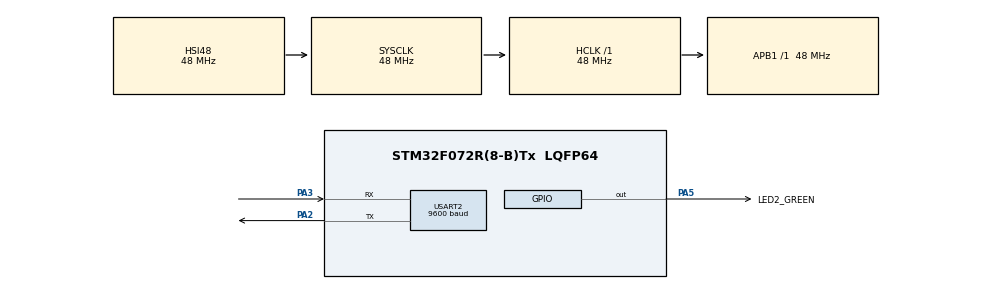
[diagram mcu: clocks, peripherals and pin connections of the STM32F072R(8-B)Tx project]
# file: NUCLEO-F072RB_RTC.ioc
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Mcu.Family=STM32F0
Mcu.Name=STM32F072R(8-B)Tx
Mcu.Package=LQFP64
NVIC.RTC_IRQn=true\:0\:0\:false\:false\:true
PA13.Mode=Serial_Wire
PA13.Signal=SYS_SWDIO
PA14.Mode=Serial_Wire
PA14.Signal=SYS_SWCLK
PA2.Mode=Asynchronous
PA2.Signal=USART2_TX
PA3.Mode=Asynchronous
PA3.Signal=USART2_RX
PA5.GPIO_Label=LED2_GREEN
PA5.Signal=GPIO_Output
ProjectManager.HeapSize=0x200
ProjectManager.StackSize=0x400
ProjectManager.TargetToolchain=EWARM
RCC.AHBFreq_Value=48000000
RCC.APB1Freq_Value=48000000
RCC.APB1TimFreq_Value=48000000
RCC.HCLKFreq_Value=48000000
RCC.SYSCLKFreq_VALUE=48000000
RCC.SYSCLKSource=RCC_SYSCLKSOURCE_HSI48
RTC.Date=30
RTC.Hours=14
RTC.Minutes=10
RTC.Month=RTC_MONTH_AUGUST
RTC.Seconds=5
RTC.WeekDay=RTC_WEEKDAY_TUESDAY
RTC.Year=16
USART2.BaudRate=9600
USART2.WordLength=UART_WORDLENGTH_8B
VP_RTC_VS_RTC_Activate.Mode=RTC_Enabled
VP_RTC_VS_RTC_Calendar.Mode=RTC_Calendar
VP_RTC_VS_RTC_WakeUp_intern.Mode=WakeUp
board=NUCLEO-F072RB_RTC

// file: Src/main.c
/**
  ******************************************************************************
  * File Name          : main.c
  * Description        : Main program body
  ******************************************************************************
  *
  * COPYRIGHT(c) 2016 STMicroelectronics
  *
  * Redistribution and use in source and binary forms, with or without modification,
  * are permitted provided that the following conditions are met:
  *   1. Redistributions of source code must retain the above copyright notice,
  *      this list of conditions and the following disclaimer.
  *   2. Redistributions in binary form must reproduce the above copyright notice,
  *      this list of conditions and the following disclaimer in the documentation
  *      and/or other materials provided with the distribution.
  *   3. Neither the name of STMicroelectronics nor the names of its contributors
  *      may be used to endorse or promote products derived from this software
  *      without specific prior written permission.
  *
  * THIS SOFTWARE IS PROVIDED BY THE COPYRIGHT HOLDERS AND CONTRIBUTORS "AS IS"
  * AND ANY EXPRESS OR IMPLIED WARRANTIES, INCLUDING, BUT NOT LIMITED TO, THE
  * IMPLIED WARRANTIES OF MERCHANTABILITY AND FITNESS FOR A PARTICULAR PURPOSE ARE
  * DISCLAIMED. IN NO EVENT SHALL THE COPYRIGHT HOLDER OR CONTRIBUTORS BE LIABLE
  * FOR ANY DIRECT, INDIRECT, INCIDENTAL, SPECIAL, EXEMPLARY, OR CONSEQUENTIAL
  * DAMAGES (INCLUDING, BUT NOT LIMITED TO, PROCUREMENT OF SUBSTITUTE GOODS OR
  * SERVICES; LOSS OF USE, DATA, OR PROFITS; OR BUSINESS INTERRUPTION) HOWEVER
  * CAUSED AND ON ANY THEORY OF LIABILITY, WHETHER IN CONTRACT, STRICT LIABILITY,
  * OR TORT (INCLUDING NEGLIGENCE OR OTHERWISE) ARISING IN ANY WAY OUT OF THE USE
  * OF THIS SOFTWARE, EVEN IF ADVISED OF THE POSSIBILITY OF SUCH DAMAGE.
  *
  ******************************************************************************
  */
#include "main.h"
#include "stm32f0xx_hal.h"
#include "rtc.h"
#include "usart.h"
#include "gpio.h"

/* USER CODE BEGIN Includes */
//------------------------------------------------------------------------------
/* Projeto    : NUCLEO-F072RB_RTC
 * MCU        : STM32F072RB (NUCLEO-F072RB)
 * Copyright  : Atribuição (CC BY 4.0) Diego Moreno
 * Versão     : 1.0.0
 * Data	      : 10/09/2016
 * Descrição  : Atualiza data e hora do RTC e manda uma string update via UART.
 *		NUCLEO-F072RB Schematics - http://migre.me/tVEOR
 */

/* Includes */
#include <stdio.h>
#include <string.h>

//------------------------------------------------------------------------------
/* USER CODE END Includes */

/* USER CODE BEGIN PV */
/* Private variables ---------------------------------------------------------*/
RTC_TimeTypeDef struct_time;
RTC_DateTypeDef struct_date;

char str_hora_data[50];
/* USER CODE END PV */

void SystemClock_Config(void);
void Error_Handler(void);

/* USER CODE BEGIN PFP */
/* Private function prototypes -----------------------------------------------*/
void RTC_hora_data(void);
/* USER CODE END PFP */

int main(void)
{

  /* MCU Configuration----------------------------------------------------------*/

  /* Reset of all peripherals, Initializes the Flash interface and the Systick. */
  HAL_Init();

  /* Configure the system clock */
  SystemClock_Config();

  /* Initialize all configured peripherals */
  MX_GPIO_Init();
  MX_RTC_Init();
  MX_USART2_UART_Init();

  /* USER CODE BEGIN 2 */

  //Setar o horário inicial
  struct_time.Hours = 0x20;
  struct_time.Minutes = 0x35;
  struct_time.Seconds = 0x45;
  if(HAL_RTC_SetTime(&hrtc, &struct_time, RTC_FORMAT_BCD) != HAL_OK)
  {
    Error_Handler();
  }

  //Setar a data inicial
  struct_date.WeekDay = RTC_WEEKDAY_TUESDAY;
  struct_date.Month = RTC_MONTH_AUGUST;
  struct_date.Date = 0x03;
  struct_date.Year = 0x16;
  if(HAL_RTC_SetDate(&hrtc, &struct_date, RTC_FORMAT_BCD) != HAL_OK)
  {
    Error_Handler();
  }

  /* USER CODE END 2 */

  /* Infinite loop */
  while (1)
  {

  /* USER CODE BEGIN 3 */

    RTC_hora_data();
    HAL_Delay(999);
  }
  /* USER CODE END 3 */

}

/** System Clock Configuration
*/
void SystemClock_Config(void)
{

  RCC_OscInitTypeDef RCC_OscInitStruct;
  RCC_ClkInitTypeDef RCC_ClkInitStruct;
  RCC_PeriphCLKInitTypeDef PeriphClkInit;

    /**Initializes the CPU, AHB and APB busses clocks
    */
  RCC_OscInitStruct.OscillatorType = RCC_OSCILLATORTYPE_HSI48|RCC_OSCILLATORTYPE_LSI;
  RCC_OscInitStruct.HSI48State = RCC_HSI48_ON;
  RCC_OscInitStruct.LSIState = RCC_LSI_ON;
  RCC_OscInitStruct.PLL.PLLState = RCC_PLL_NONE;
  if (HAL_RCC_OscConfig(&RCC_OscInitStruct) != HAL_OK)
  {
    Error_Handler();
  }

    /**Initializes the CPU, AHB and APB busses clocks
    */
  RCC_ClkInitStruct.ClockType = RCC_CLOCKTYPE_HCLK|RCC_CLOCKTYPE_SYSCLK
                              |RCC_CLOCKTYPE_PCLK1;
  RCC_ClkInitStruct.SYSCLKSource = RCC_SYSCLKSOURCE_HSI48;
  RCC_ClkInitStruct.AHBCLKDivider = RCC_SYSCLK_DIV1;
  RCC_ClkInitStruct.APB1CLKDivider = RCC_HCLK_DIV1;

  if (HAL_RCC_ClockConfig(&RCC_ClkInitStruct, FLASH_LATENCY_1) != HAL_OK)
  {
    Error_Handler();
  }

  PeriphClkInit.PeriphClockSelection = RCC_PERIPHCLK_USART2|RCC_PERIPHCLK_RTC;
  PeriphClkInit.Usart2ClockSelection = RCC_USART2CLKSOURCE_PCLK1;
  PeriphClkInit.RTCClockSelection = RCC_RTCCLKSOURCE_LSI;
  if (HAL_RCCEx_PeriphCLKConfig(&PeriphClkInit) != HAL_OK)
  {
    Error_Handler();
  }

    /**Configure the Systick interrupt time
    */
  HAL_SYSTICK_Config(HAL_RCC_GetHCLKFreq()/1000);

    /**Configure the Systick
    */
  HAL_SYSTICK_CLKSourceConfig(SYSTICK_CLKSOURCE_HCLK);

  /* SysTick_IRQn interrupt configuration */
  HAL_NVIC_SetPriority(SysTick_IRQn, 0, 0);
}

/* USER CODE BEGIN 4 */
//------------------------------------------------------------------------------

/* Subrotina  : RTC_hora_data
 * Descrição  : Atualiza hora e data e manda na serial.
 * Parâmetros : void
 * Retorno    : void
 */
void RTC_hora_data(void)
{
  //Lê a hora do RTC
  HAL_RTC_GetTime(&hrtc, &struct_time, RTC_FORMAT_BIN);
  //Lê a data do RTC
  HAL_RTC_GetDate(&hrtc, &struct_date, RTC_FORMAT_BIN);

  //Configura a hora e data em uma string
  sprintf(str_hora_data,"\n\r%02d:%02d:%02d - %02d/%02d/%02d\n\r",struct_time.Hours, struct_time.Minutes, struct_time.Seconds, struct_date.Date, struct_date.Month, struct_date.Year);

  //Manda a string via serial
  HAL_UART_Transmit(&huart2, (uint8_t*)str_hora_data, strlen(str_hora_data), 1000);
}

//------------------------------------------------------------------------------
/* USER CODE END 4 */

void Error_Handler(void)
{
  while(1)
  {
  }
}

/************************ (C) COPYRIGHT STMicroelectronics *****END OF FILE****/
